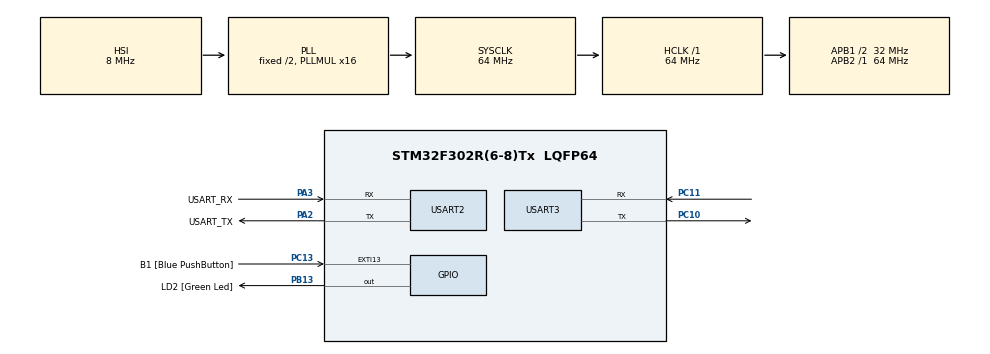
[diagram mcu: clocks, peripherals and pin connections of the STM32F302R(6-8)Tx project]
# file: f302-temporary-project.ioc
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Mcu.Family=STM32F3
NVIC.USART3_IRQn=true\:5\:0\:false\:false\:true\:true\:true\:false
PA2.GPIO_PuPd=GPIO_NOPULL
RCC.CortexFreq_Value=64000000
PC10.Signal=USART3_TX
PA14.GPIO_Label=TCK
RCC.SYSCLKSourceVirtual=RCC_SYSCLKSOURCE_PLLCLK
PA3.GPIO_PuPd=GPIO_NOPULL
PA2.GPIO_Speed=GPIO_SPEED_FREQ_LOW
PC13.GPIO_Label=B1 [Blue PushButton]
PB13.GPIO_Label=LD2 [Green Led]
PA3.GPIO_Speed=GPIO_SPEED_FREQ_LOW
PB13.Signal=GPIO_Output
ProjectManager.StackSize=0x400
VP_FREERTOS_VS_CMSIS_V2.Mode=CMSIS_V2
USART3.VirtualMode-Asynchronous=VM_ASYNC
RCC.HCLKFreq_Value=64000000
RCC.APB2TimFreq_Value=64000000
RCC.AHBFreq_Value=64000000
PC15\ -\ OSC32_OUT.Signal=RCC_OSC32_OUT
NVIC.EXTI15_10_IRQn=true\:5\:0\:true\:false\:true\:true\:true\:true
RCC.HSE_VALUE=8000000
PB3.Mode=Trace_Asynchronous_SW
USART2.VirtualMode-Asynchronous=VM_ASYNC
RCC.RCC_PLLsource_Clock_Source_FROM_HSE=RCC_HSE_PREDIV_DIV2
RCC.PLLMUL=RCC_PLL_MUL16
PA14.Mode=Serial_Wire
VP_SYS_VS_tim1.Mode=TIM1
Mcu.Package=LQFP64
NVIC.TimeBase=TIM1_UP_TIM16_IRQn
PA2.GPIO_Label=USART_TX
NVIC.TimeBaseIP=TIM1
PC11.Mode=Asynchronous
RCC.APB1TimFreq_Value=64000000
PF1-OSC_OUT.Signal=RCC_OSC_OUT
PA3.Signal=USART2_RX
PA2.GPIO_Mode=GPIO_MODE_AF_PP
PB3.GPIO_Label=SWO
FREERTOS.Tasks01=defaultTask,24,128,StartDefaultTask,Default,NULL,Dynamic,NULL,NULL
PC13.Signal=GPXTI13
PC11.Signal=USART3_RX
PC10.Mode=Asynchronous
RCC.APB1CLKDivider=RCC_HCLK_DIV2
PA13.Signal=SYS_JTMS-SWDIO
PA3.Mode=Asynchronous
PC14\ -\ OSC32_IN.Mode=LSE-External-Oscillator
ProjectManager.TargetToolchain=Makefile
PA3.GPIO_Mode=GPIO_MODE_AF_PP
RCC.USBFreq_Value=64000000
PF0-OSC_IN.Mode=HSE-External-Clock-Source
board=NUCLEO-F302R8
RCC.APB2Freq_Value=64000000
PA13.Mode=Serial_Wire
Mcu.Name=STM32F302R(6-8)Tx
PA13.GPIO_Label=TMS
PA2.Signal=USART2_TX
PB3.Signal=SYS_JTDO-TRACESWO
RCC.SYSCLKFreq_VALUE=64000000
PC13.GPIO_ModeDefaultEXTI=GPIO_MODE_IT_FALLING
PA14.Signal=SYS_JTCK-SWCLK
PC15\ -\ OSC32_OUT.Mode=LSE-External-Oscillator
ProjectManager.HeapSize=0x200
RCC.HSI_VALUE=8000000
NVIC.TIM1_UP_TIM16_IRQn=true\:0\:0\:false\:false\:true\:false\:false\:true
RCC.PLLP=RCC_PLLP_DIV4
RCC.PLLQ=7
NVIC.PriorityGroup=NVIC_PRIORITYGROUP_4
RCC.PLLM=8
RCC.PLLN=336
PA2.Mode=Asynchronous
PF0-OSC_IN.Signal=RCC_OSC_IN
RCC.APB1Freq_Value=32000000
VP_CRC_VS_CRC.Mode=CRC_Activate
PA3.GPIO_Label=USART_RX
PC14\ -\ OSC32_IN.Signal=RCC_OSC32_IN

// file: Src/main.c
/* USER CODE BEGIN Header */
/**
  ******************************************************************************
  * @file           : main.c
  * @brief          : Main program body
  ******************************************************************************
  * @attention
  *
  * <h2><center>&copy; Copyright (c) 2020 STMicroelectronics.
  * All rights reserved.</center></h2>
  *
  * This software component is licensed by ST under BSD 3-Clause license,
  * the "License"; You may not use this file except in compliance with the
  * License. You may obtain a copy of the License at:
  *                        opensource.org/licenses/BSD-3-Clause
  *
  ******************************************************************************
  */
/* USER CODE END Header */

#include "main.h"
#include "cmsis_os.h"

/* USER CODE BEGIN Includes */
#include <string.h>
#include <stdio.h>
#include "task_uart_receiver.h"
#include "task_button.h"

/* USER CODE END Includes */

CRC_HandleTypeDef hcrc;

UART_HandleTypeDef huart2;
UART_HandleTypeDef huart3;

/* Definitions for defaultTask */
osThreadId_t defaultTaskHandle;
const osThreadAttr_t defaultTask_attributes = {
  .name = "defaultTask",
  .priority = (osPriority_t) osPriorityNormal,
  .stack_size = 128 * 4
};
/* USER CODE BEGIN PV */
const osThreadAttr_t buttonTask_attributes = {
  .name = "button_task",
  .priority = (osPriority_t) osPriorityNormal,
  .stack_size = 256 * 4
};

/* USER CODE END PV */

void SystemClock_Config(void);
static void MX_GPIO_Init(void);
static void MX_USART2_UART_Init(void);
static void MX_USART3_UART_Init(void);
static void MX_CRC_Init(void);
void StartDefaultTask(void *argument);

int main(void)
{

  /* MCU Configuration--------------------------------------------------------*/

  /* Reset of all peripherals, Initializes the Flash interface and the Systick. */
  HAL_Init();

  /* Configure the system clock */
  SystemClock_Config();

  /* Initialize all configured peripherals */
  MX_GPIO_Init();
  MX_USART2_UART_Init();
  MX_USART3_UART_Init();
  MX_CRC_Init();
  /* USER CODE BEGIN 2 */
  __HAL_UART_ENABLE_IT(&huart3, UART_IT_RXNE);

  /* USER CODE END 2 */

  /* Init scheduler */
  osKernelInitialize();

  /* Create the thread(s) */
  /* creation of defaultTask */
  defaultTaskHandle = osThreadNew(StartDefaultTask, NULL, &defaultTask_attributes);

  /* USER CODE BEGIN RTOS_THREADS */
  /* add threads, ... */
  osThreadNew(task_uart_receiver, NULL, &defaultTask_attributes);
  osThreadNew(task_button, NULL, &buttonTask_attributes);

  /* USER CODE END RTOS_THREADS */

  /* Start scheduler */
  osKernelStart();

  /* We should never get here as control is now taken by the scheduler */
  /* Infinite loop */
  while (1)
  {

  }
}

void SystemClock_Config(void)
{
  RCC_OscInitTypeDef RCC_OscInitStruct = {0};
  RCC_ClkInitTypeDef RCC_ClkInitStruct = {0};

  /** Initializes the CPU, AHB and APB busses clocks
  */
  RCC_OscInitStruct.OscillatorType = RCC_OSCILLATORTYPE_HSI;
  RCC_OscInitStruct.HSIState = RCC_HSI_ON;
  RCC_OscInitStruct.HSICalibrationValue = RCC_HSICALIBRATION_DEFAULT;
  RCC_OscInitStruct.PLL.PLLState = RCC_PLL_ON;
  RCC_OscInitStruct.PLL.PLLSource = RCC_PLLSOURCE_HSI;
  RCC_OscInitStruct.PLL.PLLMUL = RCC_PLL_MUL16;
  if (HAL_RCC_OscConfig(&RCC_OscInitStruct) != HAL_OK)
  {
    Error_Handler();
  }
  /** Initializes the CPU, AHB and APB busses clocks
  */
  RCC_ClkInitStruct.ClockType = RCC_CLOCKTYPE_HCLK|RCC_CLOCKTYPE_SYSCLK
                              |RCC_CLOCKTYPE_PCLK1|RCC_CLOCKTYPE_PCLK2;
  RCC_ClkInitStruct.SYSCLKSource = RCC_SYSCLKSOURCE_PLLCLK;
  RCC_ClkInitStruct.AHBCLKDivider = RCC_SYSCLK_DIV1;
  RCC_ClkInitStruct.APB1CLKDivider = RCC_HCLK_DIV2;
  RCC_ClkInitStruct.APB2CLKDivider = RCC_HCLK_DIV1;

  if (HAL_RCC_ClockConfig(&RCC_ClkInitStruct, FLASH_LATENCY_2) != HAL_OK)
  {
    Error_Handler();
  }
}

static void MX_CRC_Init(void)
{

  hcrc.Instance = CRC;
  hcrc.Init.DefaultPolynomialUse = DEFAULT_POLYNOMIAL_ENABLE;
  hcrc.Init.DefaultInitValueUse = DEFAULT_INIT_VALUE_ENABLE;
  hcrc.Init.InputDataInversionMode = CRC_INPUTDATA_INVERSION_NONE;
  hcrc.Init.OutputDataInversionMode = CRC_OUTPUTDATA_INVERSION_DISABLE;
  hcrc.InputDataFormat = CRC_INPUTDATA_FORMAT_BYTES;
  if (HAL_CRC_Init(&hcrc) != HAL_OK)
  {
    Error_Handler();
  }

}

static void MX_USART2_UART_Init(void)
{

  huart2.Instance = USART2;
  huart2.Init.BaudRate = 38400;
  huart2.Init.WordLength = UART_WORDLENGTH_8B;
  huart2.Init.StopBits = UART_STOPBITS_1;
  huart2.Init.Parity = UART_PARITY_NONE;
  huart2.Init.Mode = UART_MODE_TX_RX;
  huart2.Init.HwFlowCtl = UART_HWCONTROL_NONE;
  huart2.Init.OverSampling = UART_OVERSAMPLING_16;
  huart2.Init.OneBitSampling = UART_ONE_BIT_SAMPLE_DISABLE;
  huart2.AdvancedInit.AdvFeatureInit = UART_ADVFEATURE_NO_INIT;
  if (HAL_UART_Init(&huart2) != HAL_OK)
  {
    Error_Handler();
  }

}

static void MX_USART3_UART_Init(void)
{

  huart3.Instance = USART3;
  huart3.Init.BaudRate = 38400;
  huart3.Init.WordLength = UART_WORDLENGTH_8B;
  huart3.Init.StopBits = UART_STOPBITS_1;
  huart3.Init.Parity = UART_PARITY_NONE;
  huart3.Init.Mode = UART_MODE_TX_RX;
  huart3.Init.HwFlowCtl = UART_HWCONTROL_NONE;
  huart3.Init.OverSampling = UART_OVERSAMPLING_16;
  huart3.Init.OneBitSampling = UART_ONE_BIT_SAMPLE_DISABLE;
  huart3.AdvancedInit.AdvFeatureInit = UART_ADVFEATURE_NO_INIT;
  if (HAL_UART_Init(&huart3) != HAL_OK)
  {
    Error_Handler();
  }

}

static void MX_GPIO_Init(void)
{
  GPIO_InitTypeDef GPIO_InitStruct = {0};

  /* GPIO Ports Clock Enable */
  __HAL_RCC_GPIOC_CLK_ENABLE();
  __HAL_RCC_GPIOF_CLK_ENABLE();
  __HAL_RCC_GPIOA_CLK_ENABLE();
  __HAL_RCC_GPIOB_CLK_ENABLE();

  /*Configure GPIO pin Output Level */
  HAL_GPIO_WritePin(LD2_GPIO_Port, LD2_Pin, GPIO_PIN_RESET);

  /*Configure GPIO pin : B1_Pin */
  GPIO_InitStruct.Pin = B1_Pin;
  GPIO_InitStruct.Mode = GPIO_MODE_IT_FALLING;
  GPIO_InitStruct.Pull = GPIO_NOPULL;
  HAL_GPIO_Init(B1_GPIO_Port, &GPIO_InitStruct);

  /*Configure GPIO pin : LD2_Pin */
  GPIO_InitStruct.Pin = LD2_Pin;
  GPIO_InitStruct.Mode = GPIO_MODE_OUTPUT_PP;
  GPIO_InitStruct.Pull = GPIO_NOPULL;
  GPIO_InitStruct.Speed = GPIO_SPEED_FREQ_LOW;
  HAL_GPIO_Init(LD2_GPIO_Port, &GPIO_InitStruct);

  /* EXTI interrupt init*/
  HAL_NVIC_SetPriority(EXTI15_10_IRQn, 5, 0);
  HAL_NVIC_EnableIRQ(EXTI15_10_IRQn);

}

void StartDefaultTask(void *argument)
{
  /* USER CODE BEGIN 5 */
  osThreadId_t id = osThreadGetId();
  osThreadTerminate(id);

  /* Infinite loop */
  /* USER CODE END 5 */
}

 /**
  * @brief  Period elapsed callback in non blocking mode
  * @note   This function is called  when TIM1 interrupt took place, inside
  * HAL_TIM_IRQHandler(). It makes a direct call to HAL_IncTick() to increment
  * a global variable "uwTick" used as application time base.
  * @param  htim : TIM handle
  * @retval None
  */
void HAL_TIM_PeriodElapsedCallback(TIM_HandleTypeDef *htim)
{
  if (htim->Instance == TIM1) {
    HAL_IncTick();
  }
}

void Error_Handler(void)
{
}

/************************ (C) COPYRIGHT STMicroelectronics *****END OF FILE****/
